AUTOSAR XML (schema 4-0-3)
package /ComponentTypes
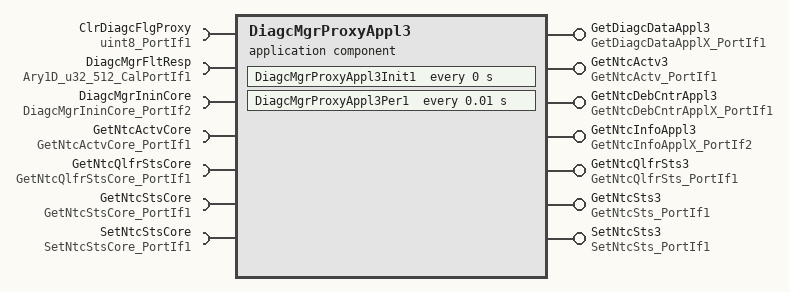
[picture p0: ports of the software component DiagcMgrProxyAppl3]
  application sw component type DiagcMgrProxyAppl3
    7 x provide port, all with server-com-spec{operation=Oper, queue-length=1}:
      GetDiagcDataAppl3: provided-interface=GetDiagcDataApplX_PortIf1
      GetNtcActv3: provided-interface=GetNtcActv_PortIf1
      GetNtcDebCntrAppl3: provided-interface=GetNtcDebCntrApplX_PortIf1
      GetNtcInfoAppl3: provided-interface=GetNtcInfoApplX_PortIf2
      GetNtcQlfrSts3: provided-interface=GetNtcQlfrSts_PortIf1
      GetNtcSts3: provided-interface=GetNtcSts_PortIf1
      SetNtcSts3: provided-interface=SetNtcSts_PortIf1
    7 x require port:
      ClrDiagcFlgProxy: nonqueued-receiver-com-spec{data-element=Val, filter=data-filter-type=ALWAYS, init-value=0}, required-interface=uint8_PortIf1
      DiagcMgrFltResp: parameter-require-com-spec{init-value=[0, 2147487488, 2147487488, 2147487488, 2147487488, 2147487488, 2147487488, 2147487488, 2147487488, 2147487488, 2147487488, 2147487488, 2147487488, 2147487488, 2147487488, 2147487488, 2147487488, 2147487488, 2147487488, 2147487488, 2147487488, 2147487488, 2147487488, 2147487488, 2147487488, 2147487488, 2147487488, 2147487488, 2147487488, 2147487488, 2147487488, 2147487488, 2147487488, 2147487488, 2147487488, 2147487488, 2147487488, 2147487488, 2147487488, 2147487488, 2147487488, 2147487488, 2147487488, 2147487488, 2147487488, 2147487488, 2147487488, 2147487488, 2147487488, 2147487488, 2147487488, 2147487488, 2147487488, 2147487488, 2147487488, 2147487488, 2147487488, 2147487488, 2147487488, 2147487488, 2147487488, 2147487488, 2147487488, 2147487488, 2147487488, 2147487488, 2147487488, 2147487488, 2147487488, 2147487488, 2147487488, 2147487488, 2147487488, 2147487488, 2147487488, 2147487488, 2147487488, 2147487488, 2147487488, 2147487488, 2147487488, 2147487488, 2147487488, 2147487488, 2147487488, 2147487488, 2147487488, 2147487488, 2147487488, 2147487488, 2147487488, 2147487488, 2147487488, 2147487488, 2147487488, 2147487488, 2147487488, 2147487488, 2147487488, 2147487488, 2147487488, 2147487488, 2147487488, 2147487488, 2147487488, 2147487488, 2147487488, 2147487488, 2147487488, 2147487488, 2147487488, 2147487488, 2147487488, 2147487488, 2147487488, 2147487488, 2147487488, 2147487488, 2147487488, 2147487488, 2147487488, 2147487488, 2147487488, 2147487488, 2147487488, 2147487488, 2147487488, 2147487488, 2147487488, 2147487488, 2147487488, 2147487488, 2147487488, 2147487488, 2147487488, 2147487488, 2147487488, 2147487488, 2147487488, 2147487488, 2147487488, 2147487488, 2147487488, 2147487488, 2147487488, 2147487488, 2147487488, 2147487488, 2147487488, 2147487488, 2147487488, 2147487488, 2147487488, 2147487488, 2147487488, 2147487488, 2147487488, 2147487488, 2147487488, 2147487488, 2147487488, 2147487488, 2147487488, 2147487488, 2147487488, 2147487488, 2147487488, 2147487488, 2147487488, 2147487488, 2147487488, 2147487488, 2147487488, 2147487488, 2147487488, 2147487488, 2147487488, 2147487488, 2147487488, 2147487488, 2147487488, 2147487488, 2147487488, 2147487488, 2147487488, 2147487488, 2147487488, 2147487488, 2147487488, 2147487488, 2147487488, 2147487488, 2147487488, 2147487488, 2147487488, 2147487488, 2147487488, 2147487488, 2147487488, 2147487488, 2147487488, 2147487488, 2147487488, 2147487488, 2147487488, 2147487488, 2147487488, 2147487488, 2147487488, 2147487488, 2147487488, 2147487488, 2147487488, 2147487488, 2147487488, 2147487488, 2147487488, 2147487488, 2147487488, 2147487488, 2147487488, 2147487488, 2147487488, 2147487488, 2147487488, 2147487488, 2147487488, 2147487488, 2147487488, 2147487488, 2147487488, 2147487488, 2147487488, 2147487488, 2147487488, 2147487488, 2147487488, 2147487488, 2147487488, 2147487488, 2147487488, 2147487488, 2147487488, 2147487488, 2147487488, 2147487488, 2147487488, 2147487488, 2147487488, 2147487488, 2147487488, 2147487488, 2147487488, 2147487488, 2147487488, 2147487488, 2147487488, 2147487488, 2147487488, 2147487488, 2147487488, 2147487488, 2147487488, 2147487488, 2147487488, 2147487488, 2147487488, 2147487488, 2147487488, 2147487488, 2147487488, 2147487488, 2147487488, 2147487488, 2147487488, 2147487488, 2147487488, 2147487488, 2147487488, 2147487488, 2147487488, 2147487488, 2147487488, 2147487488, 2147487488, 2147487488, 2147487488, 2147487488, 2147487488, 2147487488, 2147487488, 2147487488, 2147487488, 2147487488, 2147487488, 2147487488, 2147487488, 2147487488, 2147487488, 2147487488, 2147487488, 2147487488, 2147487488, 2147487488, 2147487488, 2147487488, 2147487488, 2147487488, 2147487488, 2147487488, 2147487488, 2147487488, 2147487488, 2147487488, 2147487488, 2147487488, 2147487488, 2147487488, 2147487488, 2147487488, 2147487488, 2147487488, 2147487488, 2147487488, 2147487488, 2147487488, 2147487488, 2147487488, 2147487488, 2147487488, 2147487488, 2147487488, 2147487488, 2147487488, 2147487488, 2147487488, 2147487488, 2147487488, 2147487488, 2147487488, 2147487488, 2147487488, 2147487488, 2147487488, 2147487488, 2147487488, 2147487488, 2147487488, 2147487488, 2147487488, 2147487488, 2147487488, 2147487488, 2147487488, 2147487488, 2147487488, 2147487488, 2147487488, 2147487488, 2147487488, 2147487488, 2147487488, 2147487488, 2147487488, 2147487488, 2147487488, 2147487488, 2147487488, 2147487488, 2147487488, 2147487488, 2147487488, 2147487488, 2147487488, 2147487488, 2147487488, 2147487488, 2147487488, 2147487488, 2147487488, 2147487488, 2147487488, 2147487488, 2147487488, 2147487488, 2147487488, 2147487488, 2147487488, 2147487488, 2147487488, 2147487488, 2147487488, 2147487488, 2147487488, 2147487488, 2147487488, 2147487488, 2147487488, 2147487488, 2147487488, 2147487488, 2147487488, 2147487488, 2147487488, 2147487488, 2147487488, 2147487488, 2147487488, 2147487488, 2147487488, 2147487488, 2147487488, 2147487488, 2147487488, 2147487488, 2147487488, 2147487488, 2147487488, 2147487488, 2147487488, 2147487488, 2147487488, 2147487488, 2147487488, 2147487488, 2147487488, 2147487488, 2147487488, 2147487488, 2147487488, 2147487488, 2147487488, 2147487488, 2147487488, 2147487488, 2147487488, 2147487488, 2147487488, 2147487488, 2147487488, 2147487488, 2147487488, 2147487488, 2147487488, 2147487488, 2147487488, 2147487488, 2147487488, 2147487488, 2147487488, 2147487488, 2147487488, 2147487488, 2147487488, 2147487488, 2147487488, 2147487488, 2147487488, 2147487488, 2147487488, 2147487488, 2147487488, 2147487488, 2147487488, 2147487488, 2147487488, 2147487488, 2147487488, 2147487488, 2147487488, 2147487488, 2147487488, 2147487488, 2147487488, 2147487488, 2147487488, 2147487488, 2147487488, 2147487488, 2147487488, 2147487488, 2147487488, 2147487488, 2147487488, 2147487488, 2147487488, 2147487488, 2147487488, 2147487488, 2147487488, 2147487488, 2147487488, 2147487488, 2147487488, 2147487488, 2147487488, 2147487488, 2147487488, 2147487488, 2147487488, 2147487488, 2147487488, 2147487488, 2147487488, 2147487488, 2147487488, 2147487488, 2147487488, 2147487488, 2147487488, 2147487488, 2147487488], parameter=Ary1D}, required-interface=Ary1D_u32_512_CalPortIf1
      DiagcMgrIninCore: required-interface=DiagcMgrIninCore_PortIf2
      GetNtcActvCore: required-interface=GetNtcActvCore_PortIf1
      GetNtcQlfrStsCore: required-interface=GetNtcQlfrStsCore_PortIf1
      GetNtcStsCore: required-interface=GetNtcStsCore_PortIf1
      SetNtcStsCore: required-interface=SetNtcStsCore_PortIf1
    behavior DiagcMgrProxyAppl3_InternalBehavior
      exclusive area DiagcMgrProxyAppl3
      ar-typed-per-instance-memorys:
        5 x data:
          DiagcData3: sw-calibration-access=READ-ONLY, type=DiagcDataRec1
          DiagcMgrNtcInfo3Ary: type=Ary1D_NtcInfoRec4_DiagcMgrProxyAppl3
          DiagcMgrNtcInfo3DebCntrAry: type=Ary1D_s16_DiagcMgrProxyAppl3
          PrevClrNtcFlg3: sw-calibration-access=READ-ONLY, type=uint8
          ProxySetNtcData3: sw-calibration-access=READ-ONLY, type=DiagcDataRec1
      timing event DiagcMgrProxyAppl3_InitEvent: start-on-event=DiagcMgrProxyAppl3Init1, period=0
      timing event TMT_DiagcMgrProxyAppl3Per1: start-on-event=DiagcMgrProxyAppl3Per1, period=0.01
      7 x operation invoked event:
        OIT_GetDiagcDataAppl3_Oper_GetDiagcDataAppl3_Oper: start-on-event=GetDiagcDataAppl3_Oper, operation=GetDiagcDataAppl3.Oper
        OIT_GetNtcActv3_Oper_GetNtcActv3_Oper: start-on-event=GetNtcActv3_Oper, operation=GetNtcActv3.Oper
        OIT_GetNtcDebCntrAppl3_Oper_GetNtcDebCntrAppl3_Oper: start-on-event=GetNtcDebCntrAppl3_Oper, operation=GetNtcDebCntrAppl3.Oper
        OIT_GetNtcInfoAppl3_Oper_GetNtcInfoAppl3_Oper: start-on-event=GetNtcInfoAppl3_Oper, operation=GetNtcInfoAppl3.Oper
        OIT_GetNtcQlfrSts3_Oper_GetNtcQlfrSts3_Oper: start-on-event=GetNtcQlfrSts3_Oper, operation=GetNtcQlfrSts3.Oper
        OIT_GetNtcSts3_Oper_GetNtcSts3_Oper: start-on-event=GetNtcSts3_Oper, operation=GetNtcSts3.Oper
        OIT_SetNtcSts3_Oper_SetNtcSts3_Oper: start-on-event=SetNtcSts3_Oper, operation=SetNtcSts3.Oper
      9 x runnable:
        DiagcMgrProxyAppl3Init1
          sync call SC_DiagcMgrIninCore_Oper: operation=DiagcMgrIninCore.Oper, timeout=0
        DiagcMgrProxyAppl3Per1: can-enter-exclusive-area=DiagcMgrProxyAppl3
          data-receive-point-by-arguments:
            access REC_ClrNtcFlg_Val: accessed-variable=ClrDiagcFlgProxy.Val
        GetDiagcDataAppl3_Oper
        GetNtcActv3_Oper: can-be-invoked-concurrently=true
          sync call SC_GetNtcActvCore_Oper: operation=GetNtcActvCore.Oper, timeout=0
        GetNtcDebCntrAppl3_Oper
        GetNtcInfoAppl3_Oper
        GetNtcQlfrSts3_Oper: can-be-invoked-concurrently=true
          sync call SC_GetNtcQlfrStsCore_Oper: operation=GetNtcQlfrStsCore.Oper, timeout=0
        GetNtcSts3_Oper: can-be-invoked-concurrently=true
          sync call SC_GetNtcStsCore_Oper: operation=GetNtcStsCore.Oper, timeout=0
        SetNtcSts3_Oper: can-be-invoked-concurrently=true
          sync call SC_SetNtcStsCore_Oper: operation=SetNtcStsCore.Oper, timeout=0
  swc implementation DiagcMgrProxyAppl3_Implementation: behavior=DiagcMgrProxyAppl3_InternalBehavior
    code-descriptors:
      code Default: artifact-descriptors=autosar-engineering-object={short-label=Default, category=SWSRC}
